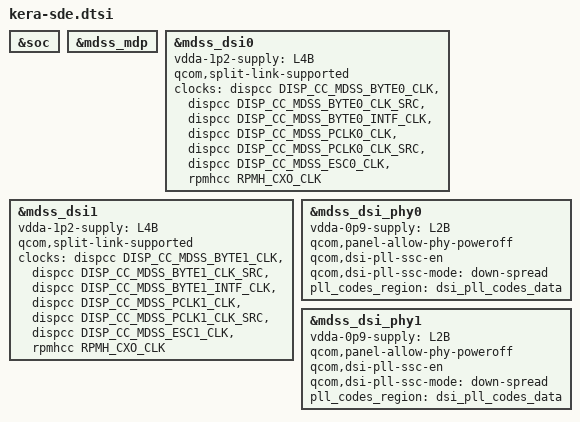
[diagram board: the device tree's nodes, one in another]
// SPDX-License-Identifier: BSD-3-Clause
/*
 * Copyright (c) 2024 Qualcomm Innovation Center, Inc. All rights reserved.
 */

#include <dt-bindings/clock/qcom,dispcc-tuna.h>
#include <dt-bindings/clock/qcom,rpmh.h>
#include "kera-sde-common.dtsi"

&soc {
};

&mdss_mdp {
};

&mdss_dsi0 {
	vdda-1p2-supply = <&L4B>;
	qcom,split-link-supported;
	clocks = <&dispcc DISP_CC_MDSS_BYTE0_CLK>,
		<&dispcc DISP_CC_MDSS_BYTE0_CLK_SRC>,
		<&dispcc DISP_CC_MDSS_BYTE0_INTF_CLK>,
		<&dispcc DISP_CC_MDSS_PCLK0_CLK>,
		<&dispcc DISP_CC_MDSS_PCLK0_CLK_SRC>,
		<&dispcc DISP_CC_MDSS_ESC0_CLK>,
		<&rpmhcc RPMH_CXO_CLK>;
	clock-names = "byte_clk", "byte_clk_rcg", "byte_intf_clk",
			"pixel_clk", "pixel_clk_rcg", "esc_clk", "xo";
};

&mdss_dsi1 {
	vdda-1p2-supply = <&L4B>;
	qcom,split-link-supported;
	clocks = <&dispcc DISP_CC_MDSS_BYTE1_CLK>,
		<&dispcc DISP_CC_MDSS_BYTE1_CLK_SRC>,
		<&dispcc DISP_CC_MDSS_BYTE1_INTF_CLK>,
		<&dispcc DISP_CC_MDSS_PCLK1_CLK>,
		<&dispcc DISP_CC_MDSS_PCLK1_CLK_SRC>,
		<&dispcc DISP_CC_MDSS_ESC1_CLK>,
		<&rpmhcc RPMH_CXO_CLK>;
	clock-names = "byte_clk", "byte_clk_rcg", "byte_intf_clk",
			"pixel_clk", "pixel_clk_rcg", "esc_clk", "xo";
};

&mdss_dsi_phy0 {
	vdda-0p9-supply = <&L2B>;
	qcom,panel-allow-phy-poweroff;
	qcom,dsi-pll-ssc-en;
	qcom,dsi-pll-ssc-mode = "down-spread";
	pll_codes_region = <&dsi_pll_codes_data>;
};

&mdss_dsi_phy1 {
	vdda-0p9-supply = <&L2B>;
	qcom,panel-allow-phy-poweroff;
	qcom,dsi-pll-ssc-en;
	qcom,dsi-pll-ssc-mode = "down-spread";
	pll_codes_region = <&dsi_pll_codes_data>;
};
